AUTOSAR XML (schema 4-0-3)
package /ComponentTypes
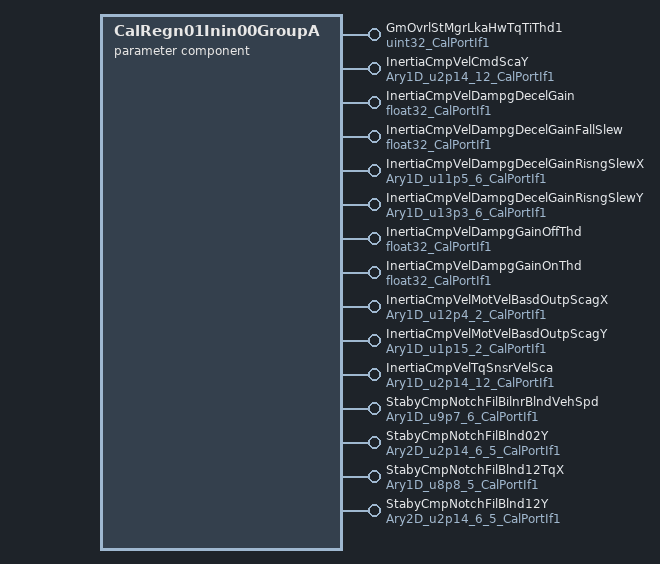
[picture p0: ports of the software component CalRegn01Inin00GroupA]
  parameter sw component type CalRegn01Inin00GroupA
    15 x provide port:
      GmOvrlStMgrLkaHwTqTiThd1: parameter-provide-com-spec{init-value=10000, parameter=Val}, provided-interface=uint32_CalPortIf1
      InertiaCmpVelCmdScaY: parameter-provide-com-spec{init-value=12 x 384, parameter=Ary1D}, provided-interface=Ary1D_u2p14_12_CalPortIf1
      InertiaCmpVelDampgDecelGain: parameter-provide-com-spec{init-value=1, parameter=Val}, provided-interface=float32_CalPortIf1
      InertiaCmpVelDampgDecelGainFallSlew: parameter-provide-com-spec{init-value=-4500, parameter=Val}, provided-interface=float32_CalPortIf1
      InertiaCmpVelDampgDecelGainRisngSlewX: parameter-provide-com-spec{init-value=[0, 640, 1088, 1120, 1152, 1184], parameter=Ary1D}, provided-interface=Ary1D_u11p5_6_CalPortIf1
      InertiaCmpVelDampgDecelGainRisngSlewY: parameter-provide-com-spec{init-value=6 x 36000, parameter=Ary1D}, provided-interface=Ary1D_u13p3_6_CalPortIf1
      InertiaCmpVelDampgGainOffThd: parameter-provide-com-spec{init-value=1, parameter=Val}, provided-interface=float32_CalPortIf1
      InertiaCmpVelDampgGainOnThd: parameter-provide-com-spec{init-value=10, parameter=Val}, provided-interface=float32_CalPortIf1
      InertiaCmpVelMotVelBasdOutpScagX: parameter-provide-com-spec{init-value=[1005, 1100], parameter=Ary1D}, provided-interface=Ary1D_u12p4_2_CalPortIf1
      InertiaCmpVelMotVelBasdOutpScagY: parameter-provide-com-spec{init-value=[32768, 32768], parameter=Ary1D}, provided-interface=Ary1D_u1p15_2_CalPortIf1
      InertiaCmpVelTqSnsrVelSca: parameter-provide-com-spec{init-value=12 x 0, parameter=Ary1D}, provided-interface=Ary1D_u2p14_12_CalPortIf1
      StabyCmpNotchFilBilnrBlndVehSpd: parameter-provide-com-spec{init-value=[0, 1280, 3840, 5760, 7680, 10240], parameter=Ary1D}, provided-interface=Ary1D_u9p7_6_CalPortIf1
      StabyCmpNotchFilBlnd02Y: parameter-provide-com-spec{init-value=6 x 5 x 16384, parameter=Ary2D}, provided-interface=Ary2D_u2p14_6_5_CalPortIf1
      StabyCmpNotchFilBlnd12TqX: parameter-provide-com-spec{init-value=[0, 512, 1024, 1536, 2048], parameter=Ary1D}, provided-interface=Ary1D_u8p8_5_CalPortIf1
      StabyCmpNotchFilBlnd12Y: parameter-provide-com-spec{init-value=6 x 5 x 0, parameter=Ary2D}, provided-interface=Ary2D_u2p14_6_5_CalPortIf1
